# LM3S6753 register map
File version: 7944
Registers are 32-bit, read-write, no defined reset value unless marked. A register's access mark holds for its fields unless they carry their own. Offsets are from the block's base; [hi:lo] are bit positions; {n}, {i} and the like mark numbered series.

## MAC — Register map for MAC peripheral
Base 0x40048000; register names take the prefix MAC
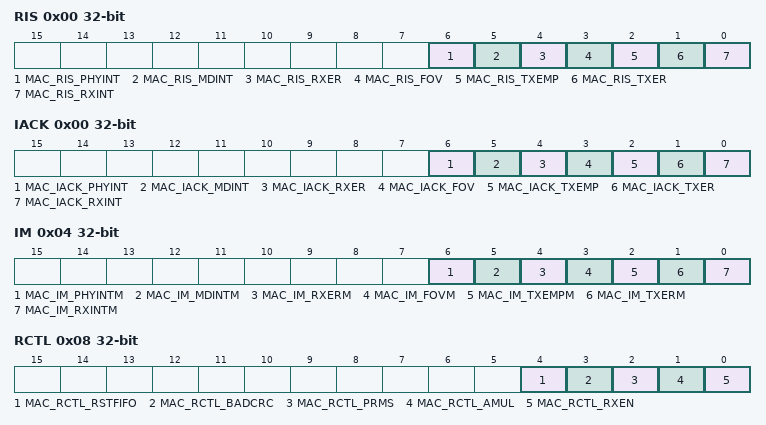
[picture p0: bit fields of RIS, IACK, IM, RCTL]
0x00 RIS — Ethernet MAC Raw Interrupt Status/Acknowledge
  [6] MAC_RIS_PHYINT — PHY Interrupt
  [5] MAC_RIS_MDINT — MII Transaction Complete
  [4] MAC_RIS_RXER — Receive Error
  [3] MAC_RIS_FOV — FIFO Overrun
  [2] MAC_RIS_TXEMP — Transmit FIFO Empty
  [1] MAC_RIS_TXER — Transmit Error
  [0] MAC_RIS_RXINT — Packet Received
0x00 IACK (MAC_ALT view) — Ethernet MAC Raw Interrupt Status/Acknowledge
  [6] MAC_IACK_PHYINT — Clear PHY Interrupt
  [5] MAC_IACK_MDINT — Clear MII Transaction Complete
  [4] MAC_IACK_RXER — Clear Receive Error
  [3] MAC_IACK_FOV — Clear FIFO Overrun
  [2] MAC_IACK_TXEMP — Clear Transmit FIFO Empty
  [1] MAC_IACK_TXER — Clear Transmit Error
  [0] MAC_IACK_RXINT — Clear Packet Received
0x04 IM — Ethernet MAC Interrupt Mask
  [6] MAC_IM_PHYINTM — Mask PHY Interrupt
  [5] MAC_IM_MDINTM — Mask MII Transaction Complete
  [4] MAC_IM_RXERM — Mask Receive Error
  [3] MAC_IM_FOVM — Mask FIFO Overrun
  [2] MAC_IM_TXEMPM — Mask Transmit FIFO Empty
  [1] MAC_IM_TXERM — Mask Transmit Error
  [0] MAC_IM_RXINTM — Mask Packet Received
0x08 RCTL — Ethernet MAC Receive Control
  [4] MAC_RCTL_RSTFIFO — Clear Receive FIFO
  [3] MAC_RCTL_BADCRC — Enable Reject Bad CRC
  [2] MAC_RCTL_PRMS — Enable Promiscuous Mode
  [1] MAC_RCTL_AMUL — Enable Multicast Frames
  [0] MAC_RCTL_RXEN — Enable Receiver
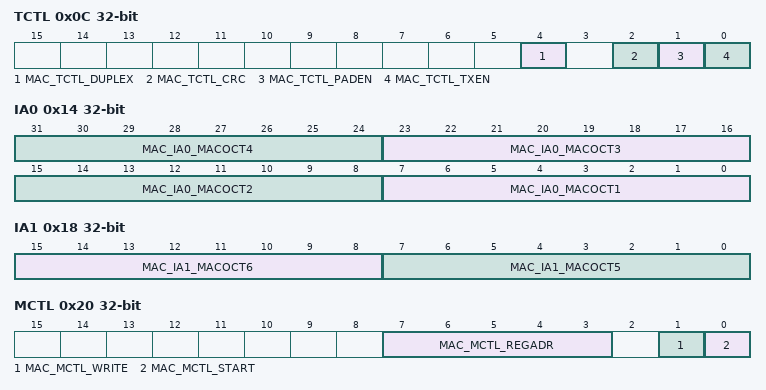
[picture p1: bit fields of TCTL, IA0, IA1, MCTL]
0x0C TCTL — Ethernet MAC Transmit Control
  [4] MAC_TCTL_DUPLEX — Enable Duplex Mode
  [2] MAC_TCTL_CRC — Enable CRC Generation
  [1] MAC_TCTL_PADEN — Enable Packet Padding
  [0] MAC_TCTL_TXEN — Enable Transmitter
0x10 DATA — Ethernet MAC Data
  [31:0] MAC_DATA_RXDATA — Receive FIFO Data
0x10 DATA (MAC_ALT view) — Ethernet MAC Data
  [31:0] MAC_DATA_TXDATA — Transmit FIFO Data
0x14 IA0 — Ethernet MAC Individual Address 0
  [8n-1:8n-8] MAC_IA0_MACOCT{n} (n=1..4) — MAC Address Octet {n}
0x18 IA1 — Ethernet MAC Individual Address 1
  [15:8] MAC_IA1_MACOCT6 — MAC Address Octet 6
  [7:0] MAC_IA1_MACOCT5 — MAC Address Octet 5
0x1C THR — Ethernet MAC Threshold
  [5:0] MAC_THR_THRESH — Threshold Value
0x20 MCTL — Ethernet MAC Management Control
  [7:3] MAC_MCTL_REGADR — MII Register Address
  [1] MAC_MCTL_WRITE — MII Register Transaction Type
  [0] MAC_MCTL_START — MII Register Transaction Enable
0x24 MDV — Ethernet MAC Management Divider
  [7:0] MAC_MDV_DIV — Clock Divider
0x2C MTXD — Ethernet MAC Management Transmit Data
  [15:0] MAC_MTXD_MDTX — MII Register Transmit Data
0x30 MRXD — Ethernet MAC Management Receive Data
  [15:0] MAC_MRXD_MDRX — MII Register Receive Data
0x34 NP — Ethernet MAC Number of Packets
  [5:0] MAC_NP_NPR — Number of Packets in Receive FIFO
0x38 TR — Ethernet MAC Transmission Request
  [0] MAC_TR_NEWTX — New Transmission
0x3C TS — Ethernet MAC Timer Support
  [0] MAC_TS_TSEN — Time Stamp Enable

## HIB — Register map for HIB peripheral
Base 0x400FC000; register names take the prefix HIB
0x00 RTCC — Hibernation RTC Counter
  [31:0] HIB_RTCC — RTC Counter
0x04 RTCM0 — Hibernation RTC Match 0
  [31:0] HIB_RTCM0 — RTC Match 0
0x08 RTCM1 — Hibernation RTC Match 1
  [31:0] HIB_RTCM1 — RTC Match 1
0x0C RTCLD — Hibernation RTC Load
  [31:0] HIB_RTCLD — RTC Load
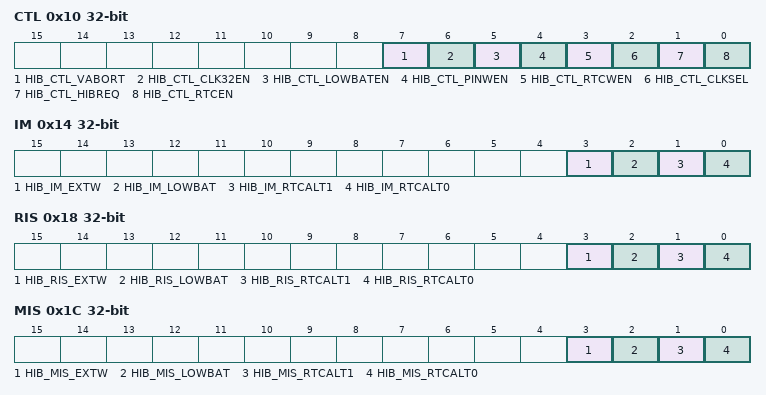
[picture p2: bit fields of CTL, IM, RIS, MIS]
0x10 CTL — Hibernation Control
  [7] HIB_CTL_VABORT — Power Cut Abort Enable
  [6] HIB_CTL_CLK32EN — Clocking Enable
  [5] HIB_CTL_LOWBATEN — Low Battery Monitoring Enable
  [4] HIB_CTL_PINWEN — External WAKE Pin Enable
  [3] HIB_CTL_RTCWEN — RTC Wake-up Enable
  [2] HIB_CTL_CLKSEL — Hibernation Module Clock Select
  [1] HIB_CTL_HIBREQ — Hibernation Request
  [0] HIB_CTL_RTCEN — RTC Timer Enable
0x14 IM — Hibernation Interrupt Mask
  [3] HIB_IM_EXTW — External Wake-Up Interrupt Mask
  [2] HIB_IM_LOWBAT — Low Battery Voltage Interrupt Mask
  [1] HIB_IM_RTCALT1 — RTC Alert 1 Interrupt Mask
  [0] HIB_IM_RTCALT0 — RTC Alert 0 Interrupt Mask
0x18 RIS — Hibernation Raw Interrupt Status
  [3] HIB_RIS_EXTW — External Wake-Up Raw Interrupt Status
  [2] HIB_RIS_LOWBAT — Low Battery Voltage Raw Interrupt Status
  [1] HIB_RIS_RTCALT1 — RTC Alert 1 Raw Interrupt Status
  [0] HIB_RIS_RTCALT0 — RTC Alert 0 Raw Interrupt Status
0x1C MIS — Hibernation Masked Interrupt Status
  [3] HIB_MIS_EXTW — External Wake-Up Masked Interrupt Status
  [2] HIB_MIS_LOWBAT — Low Battery Voltage Masked Interrupt Status
  [1] HIB_MIS_RTCALT1 — RTC Alert 1 Masked Interrupt Status
  [0] HIB_MIS_RTCALT0 — RTC Alert 0 Masked Interrupt Status
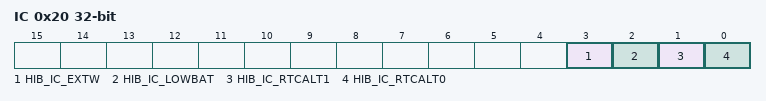
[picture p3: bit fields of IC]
0x20 IC — Hibernation Interrupt Clear
  [3] HIB_IC_EXTW — External Wake-Up Masked Interrupt Clear
  [2] HIB_IC_LOWBAT — Low Battery Voltage Masked Interrupt Clear
  [1] HIB_IC_RTCALT1 — RTC Alert1 Masked Interrupt Clear
  [0] HIB_IC_RTCALT0 — RTC Alert0 Masked Interrupt Clear
0x24 RTCT — Hibernation RTC Trim
  [15:0] HIB_RTCT_TRIM — RTC Trim Value
0x30 DATA — Hibernation Data
  [31:0] HIB_DATA_RTD — Hibernation Module NV Data

## FLASH_CTRL — Register map for FLASH_CTRL peripheral
Base 0x400FD000; register names take the prefix FLASH_CTRL
0x00 FMA — Flash Memory Address
  [16:0] FLASH_FMA_OFFSET — Address Offset
0x04 FMD — Flash Memory Data
  [31:0] FLASH_FMD_DATA — Data Value
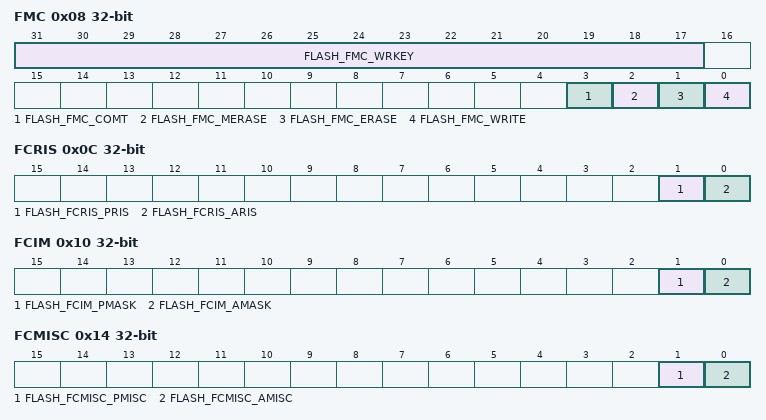
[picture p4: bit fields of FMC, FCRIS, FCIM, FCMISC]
0x08 FMC — Flash Memory Control
  [31:17] FLASH_FMC_WRKEY — FLASH write key
  [3] FLASH_FMC_COMT — Commit Register Value
  [2] FLASH_FMC_MERASE — Mass Erase Flash Memory
  [1] FLASH_FMC_ERASE — Erase a Page of Flash Memory
  [0] FLASH_FMC_WRITE — Write a Word into Flash Memory
0x0C FCRIS — Flash Controller Raw Interrupt Status
  [1] FLASH_FCRIS_PRIS — Programming Raw Interrupt Status
  [0] FLASH_FCRIS_ARIS — Access Raw Interrupt Status
0x10 FCIM — Flash Controller Interrupt Mask
  [1] FLASH_FCIM_PMASK — Programming Interrupt Mask
  [0] FLASH_FCIM_AMASK — Access Interrupt Mask
0x14 FCMISC — Flash Controller Masked Interrupt Status and Clear
  [1] FLASH_FCMISC_PMISC — Programming Masked Interrupt Status and Clear
  [0] FLASH_FCMISC_AMISC — Access Masked Interrupt Status and Clear
0x1140 USECRL — USec Reload
  [7:0] FLASH_USECRL — Microsecond Reload Value
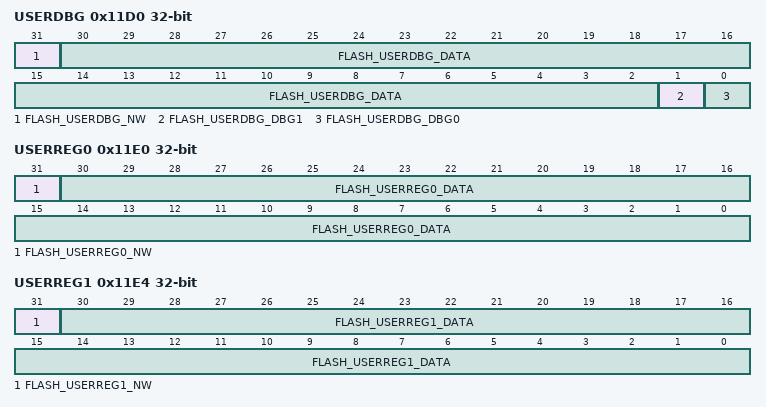
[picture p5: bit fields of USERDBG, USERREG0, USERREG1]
0x11D0 USERDBG (FLASH_ALT view) — User Debug
  [31] FLASH_USERDBG_NW — User Debug Not Written
  [30:2] FLASH_USERDBG_DATA — User Data
  [1] FLASH_USERDBG_DBG1 — Debug Control 1
  [0] FLASH_USERDBG_DBG0 — Debug Control 0
0x11E0 USERREG0 — User Register 0
  [31] FLASH_USERREG0_NW — Not Written
  [30:0] FLASH_USERREG0_DATA — User Data
0x11E4 USERREG1 — User Register 1
  [31] FLASH_USERREG1_NW — Not Written
  [30:0] FLASH_USERREG1_DATA — User Data
{0x1200+4i} FMPRE{i} (i=0..3) — Flash Memory Protection Read Enable {i}
{0x1400+4i} FMPPE{i} (i=0..3) — Flash Memory Protection Program Enable {i}
